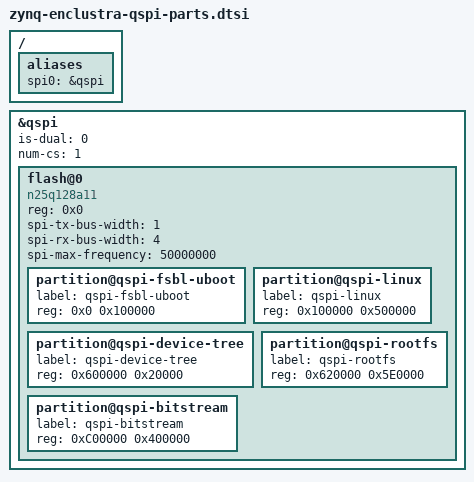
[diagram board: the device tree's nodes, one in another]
/ {
  aliases {
    spi0 = &qspi;
  };
};

&qspi {
	status = "okay";
	is-dual = <0>;
	num-cs = <1>;
	flash@0 {
		compatible = "n25q128a11";
		reg = <0x0>;
		spi-tx-bus-width = <1>;
		spi-rx-bus-width = <4>;
		spi-max-frequency = <50000000>;
		#address-cells = <1>;
		#size-cells = <1>;
		partition@qspi-fsbl-uboot {
			label = "qspi-fsbl-uboot";
			reg = <0x0 0x100000>;
		};
		partition@qspi-linux {
			label = "qspi-linux";
			reg = <0x100000 0x500000>;
		};
		partition@qspi-device-tree {
			label = "qspi-device-tree";
			reg = <0x600000 0x20000>;
		};
		partition@qspi-rootfs {
			label = "qspi-rootfs";
			reg = <0x620000 0x5E0000>;
		};
		partition@qspi-bitstream {
			label = "qspi-bitstream";
			reg = <0xC00000 0x400000>;
		};
	};
};
